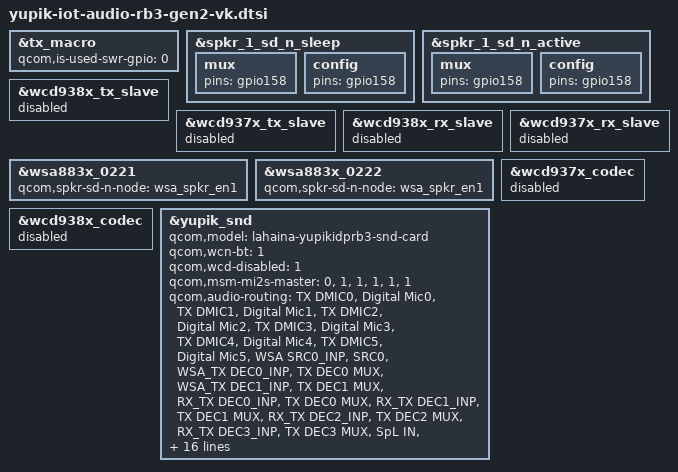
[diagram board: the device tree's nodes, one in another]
// SPDX-License-Identifier: BSD-3-Clause
/*
 * Copyright (c) Qualcomm Technologies, Inc. and/or its subsidiaries.
 */

#include "yupik-iot-audio-overlay.dtsi"

&tx_macro {
	/delete-property/ qcom,tx-swr-gpios;
	qcom,is-used-swr-gpio = <0>;
};

&spkr_1_sd_n_sleep {
	mux {
		pins = "gpio158";
	};

	config {
		pins = "gpio158";
	};
};

&spkr_1_sd_n_active {
	mux {
		pins = "gpio158";
	};

	config {
		pins = "gpio158";
	};
};

&wcd938x_tx_slave {
	status = "disabled";
};

&wcd937x_tx_slave {
	status = "disabled";
};

&wcd938x_rx_slave {
	status = "disabled";
};

&wcd937x_rx_slave {
	status = "disabled";
};

&wsa883x_0221 {
	status = "okay";
	qcom,spkr-sd-n-node = <&wsa_spkr_en1>;
};

&wsa883x_0222 {
	status = "okay";
	qcom,spkr-sd-n-node = <&wsa_spkr_en1>;
};

&wcd937x_codec {
	status = "disabled";
};

&wcd938x_codec {
	status = "disabled";
};

&yupik_snd {
	/delete-property/ fsa4480-i2c-handle;
	/delete-property/ qcom,cdc-dmic23-gpios;
	/delete-property/ qcom,cdc-dmic45-gpios;
	qcom,model = "lahaina-yupikidprb3-snd-card";
	qcom,wcn-bt = <1>;
	qcom,wcd-disabled = <1>;
	qcom,msm-mi2s-master = <0>, <1>, <1>, <1>, <1>, <1>;
	qcom,audio-routing =
		"TX DMIC0", "Digital Mic0",
		"TX DMIC1", "Digital Mic1",
		"TX DMIC2", "Digital Mic2",
		"TX DMIC3", "Digital Mic3",
		"TX DMIC4", "Digital Mic4",
		"TX DMIC5", "Digital Mic5",
		"WSA SRC0_INP", "SRC0",
		"WSA_TX DEC0_INP", "TX DEC0 MUX",
		"WSA_TX DEC1_INP", "TX DEC1 MUX",
		"RX_TX DEC0_INP", "TX DEC0 MUX",
		"RX_TX DEC1_INP", "TX DEC1 MUX",
		"RX_TX DEC2_INP", "TX DEC2 MUX",
		"RX_TX DEC3_INP", "TX DEC3 MUX",
		"SpL IN", "WSA_SPK1 OUT",
		"SpR IN", "WSA_SPK2 OUT",
		"VA SWR_INPUT", "VA_SWR_CLK",
		"VA_AIF1 CAP", "VA_SWR_CLK",
		"VA_AIF2 CAP", "VA_SWR_CLK",
		"VA_AIF3 CAP", "VA_SWR_CLK",
		"VA DMIC0", "Digital Mic0",
		"VA DMIC1", "Digital Mic1",
		"VA DMIC2", "Digital Mic2",
		"VA DMIC3", "Digital Mic3",
		"VA DMIC4", "Digital Mic4",
		"VA DMIC5", "Digital Mic5";
	qcom,pri-mi2s-gpios = <&cdc_pri_mi2s_gpios>;
	qcom,sec-mi2s-gpios = <&cdc_sec_mi2s_gpios>;
	qcom,quat-mi2s-gpios = <&cdc_quat_mi2s_gpios>;
	asoc-codec  = <&stub_codec>, <&bolero>,
		      <&wsa883x_0221>, <&wsa883x_0222>,
		      <&ext_disp_audio_codec>;
	asoc-codec-names = "msm-stub-codec.1", "bolero_codec",
			   "wsa-codec1", "wsa-codec2",
			   "msm-ext-disp-audio-codec-rx";

};

